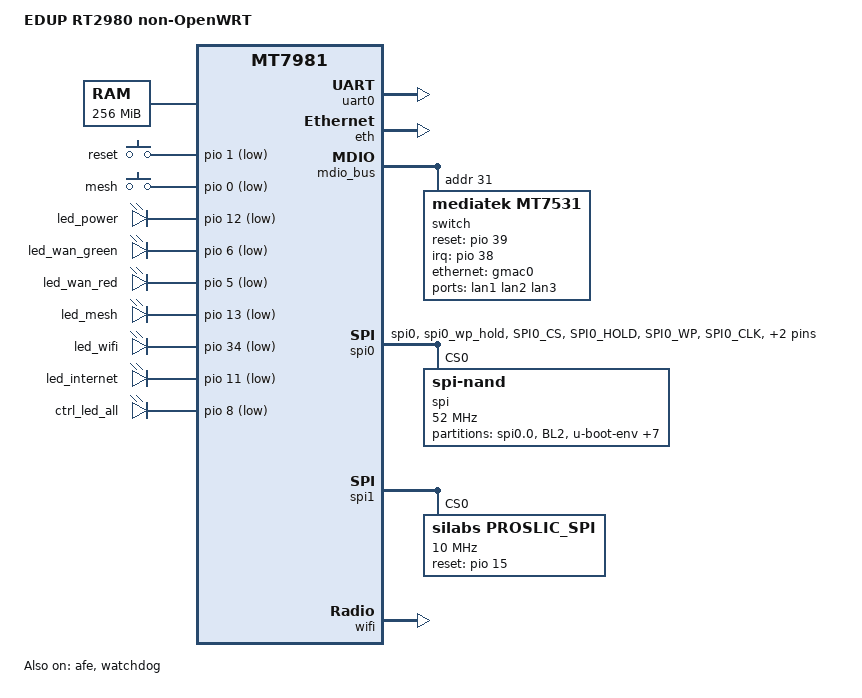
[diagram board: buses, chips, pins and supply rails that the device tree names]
// SPDX-License-Identifier: GPL-2.0-only OR MIT

/dts-v1/;
#include <dt-bindings/gpio/gpio.h>
#include <dt-bindings/input/input.h>
#include <dt-bindings/leds/common.h>

#include "mt7981.dtsi"

/ {
	model = "EDUP RT2980 non-OpenWRT";
	compatible = "edup,rt2980-non_openwrt", "mediatek,mt7981";

	aliases {
		led-boot = &power_led;
		led-failsafe = &power_led;
		led-running = &system_led;
		led-upgrade = &system_led;
		#label-mac-device = &gmac0;
		serial0 = &uart0;
	};

	chosen {
		bootargs = "console=ttyS0,115200n1 loglevel=8  \
				earlycon=uart8250,mmio32,0x11002000";
	};

	memory {
		reg = <0 0x40000000 0 0x10000000>;
	};

	gpio-keys {
		compatible = "gpio-keys";

		reset-button {
			label = "reset";
			linux,code = <KEY_RESTART>;
			gpios = <&pio 1 GPIO_ACTIVE_LOW>;
		};

		mesh-button {
			label = "mesh";
			linux,code = <BTN_9>;
			linux,input-type = <EV_SW>;
			gpios = <&pio 0 GPIO_ACTIVE_LOW>;
			debounce-interval = <60>;
		};
	};

	leds {
		compatible = "gpio-leds";

		power_led: power_red {
			label = "led_power";
			gpios = <&pio 12 GPIO_ACTIVE_LOW>;
			default-state = "on";
			linux,default-trigger = "default-on";
		};

		system_led: wan_green {
			label = "led_wan_green";
			gpios = <&pio 6 GPIO_ACTIVE_LOW>;
		};

		wan_red {
			label = "led_wan_red";
			gpios = <&pio 5 GPIO_ACTIVE_LOW>;
			linux,default-trigger = "phy1tpt";
		};

		mesh_blue {
			label = "led_mesh";
			gpios = <&pio 13 GPIO_ACTIVE_LOW>;
		};

		wifi_green {
			label = "led_wifi";
			gpios = <&pio 34 GPIO_ACTIVE_LOW>;
		};

		internet_blue {
			label = "led_internet";
			gpios = <&pio 11 GPIO_ACTIVE_LOW>;
		};

		all_ctrl {
			label = "ctrl_led_all";
			gpios = <&pio 8 GPIO_ACTIVE_LOW>;
			default-state = "on";
			linux,default-trigger = "default-on";
		};
	};
/*
	sound_wm8960 {
		compatible = "mediatek,mt79xx-wm8960-machine";
		mediatek,platform = <&afe>;
		audio-routing = "Headphone", "HP_L",
				"Headphone", "HP_R",
				"LINPUT1", "AMIC",
				"RINPUT1", "AMIC";
		mediatek,audio-codec = <&wm8960>;
		status = "disabled";
	};

	sound_si3218x {
		compatible = "mediatek,mt79xx-si3218x-machine";
		mediatek,platform = <&afe>;
		mediatek,ext-codec = <&proslic_spi>;
		status = "disabled";
	};
*/
/*
	gsw: gsw@0 {
		compatible = "mediatek,mt753x";
		mediatek,ethsys = <&ethsys>;
		#address-cells = <1>;
		#size-cells = <0>;
	};
*/
};

&afe {
	pinctrl-names = "default";
	pinctrl-0 = <&pcm_pins>;
	status = "okay";
};

&i2c0 {
	pinctrl-names = "default";
	pinctrl-0 = <&i2c_pins>;
	status = "disabled";

	wm8960: wm8960@1a {
		compatible = "wlf,wm8960";
		reg = <0x1a>;
	};
};

&uart0 {
	status = "okay";
};

&watchdog {
	status = "okay";
};

&eth {
	status = "okay";

	gmac0: mac@0 {
		compatible = "mediatek,eth-mac";
		reg = <0>;
		phy-mode = "2500base-x";

		fixed-link {
			speed = <2500>;
			full-duplex;
			pause;
		};
	};

	gmac1: mac@1 {
		compatible = "mediatek,eth-mac";
		reg = <1>;
		phy-mode = "gmii";
		phy-handle = <&int_gbe_phy>;
	};
};

&mdio_bus {
	switch: switch@1f {
		compatible = "mediatek,mt7531";
		reg = <31>;
		reset-gpios = <&pio 39 GPIO_ACTIVE_HIGH>;
		interrupt-controller;
		#interrupt-cells = <1>;
		interrupt-parent = <&pio>;
		interrupts = <38 IRQ_TYPE_LEVEL_HIGH>;
	};
};

&spi0 {
	pinctrl-names = "default";
	pinctrl-0 = <&spi0_flash_pins>;
	status = "okay";

	/* ESMT F50L1G41LB (128M) */
	spi: spi_nand@0 {
		#address-cells = <1>;
		#size-cells = <1>;
		compatible = "spi-nand";
		reg = <0>;

		spi-max-frequency = <52000000>;
		spi-tx-bus-width = <4>;
		spi-rx-bus-width = <4>;

		spi-cal-enable;
		spi-cal-mode = "read-data";
		spi-cal-datalen = <7>;
		spi-cal-data = /bits/ 8 <0x53 0x50 0x49 0x4e 0x41 0x4e 0x44>;
		spi-cal-addrlen = <5>;
		spi-cal-addr = /bits/ 32 <0x0 0x0 0x0 0x0 0x0>;

		partitions: partitions {
			compatible = "fixed-partitions";
			#address-cells = <1>;
			#size-cells = <1>;

			partition@0_all {
				label = "spi0.0";
				reg = <0x0 0x8000000>;
				read-only;
			};

			partition@0 {
				label = "BL2";
				reg = <0x00 0x100000>;
			};

			partition@100000 {
				label = "u-boot-env";
				reg = <0x100000 0x80000>;
			};

			partition@180000 {
				label = "Factory";
				reg = <0x180000 0x200000>;
			};

			partition@380000 {
				label = "FIP";
				reg = <0x380000 0x200000>;
			};

			partition@580000 {
				label = "ubi";
				reg = <0x580000 0x4000000>;
			};

			partition@4580000 {
				label = "pdt_data";
				reg = <0x4580000 0x0600000>;
				read-only;
			};

			partition@4b80000 {
				label = "pdt_data_1";
				reg = <0x4b80000 0x0600000>;
				read-only;
			};

			partition@5180000 {
				label = "exp";
				reg = <0x5180000 0x0100000>;
			};

			partition@5280000 {
				label = "plugin";
				reg = <0x5280000 0x2580000>;
			};
		};
	};
};

&spi1 {
	pinctrl-names = "default";
	pinctrl-0 = <&spic_pins>;
	status = "okay";

	proslic_spi: proslic_spi@0 {
		compatible = "silabs,proslic_spi";
		reg = <0>;
		spi-max-frequency = <10000000>;
		spi-cpha = <1>;
		spi-cpol = <1>;
		channel_count = <1>;
		debug_level = <4>;       /* 1 = TRC, 2 = DBG, 4 = ERR */
		reset_gpio = <&pio 15 0>;
		ig,enable-spi = <1>;     /* 1: Enable, 0: Disable */
	};
};

&switch {
	ports {
		#address-cells = <1>;
		#size-cells = <0>;

		port@0 {
			reg = <0>;
			label = "lan1";
		};

		port@1 {
			reg = <1>;
			label = "lan2";
		};

		port@2 {
			reg = <2>;
			label = "lan3";
		};

		port@6 {
			reg = <6>;
			ethernet = <&gmac0>;
			phy-mode = "2500base-x";

			fixed-link {
				speed = <2500>;
				full-duplex;
				pause;
			};
		};
	};
};

&pio {
	i2c_pins: i2c-pins-g0 {
		mux {
			function = "i2c";
			groups = "i2c0_0";
		};
	};

	pcm_pins: pcm-pins-g0 {
		mux {
			function = "pcm";
			groups = "pcm";
		};
	};

	pwm0_pin: pwm0-pin-g0 {
		mux {
			function = "pwm";
			groups = "pwm0_0";
		};
	};

	pwm1_pin: pwm1-pin-g0 {
		mux {
			function = "pwm";
			groups = "pwm1_0";
		};
	};

	pwm2_pin: pwm2-pin {
		mux {
			function = "pwm";
			groups = "pwm2";
		};
	};

	spi0_flash_pins: spi0-pins {
		mux {
			function = "spi";
			groups = "spi0", "spi0_wp_hold";
		};

		conf-pu {
			pins = "SPI0_CS", "SPI0_HOLD", "SPI0_WP";
			drive-strength = <MTK_DRIVE_8mA>;
			bias-pull-up = <MTK_PUPD_SET_R1R0_11>;
		};

		conf-pd {
			pins = "SPI0_CLK", "SPI0_MOSI", "SPI0_MISO";
			drive-strength = <MTK_DRIVE_8mA>;
			bias-pull-down = <MTK_PUPD_SET_R1R0_11>;
		};
	};

	uart1_pins: uart1-pins-g1 {
		mux {
			function = "uart";
			groups = "uart1_1";
		};
	};

	uart2_pins: uart2-pins-g1 {
		mux {
			function = "uart";
			groups = "uart2_1";
		};
	};
};
/*
&pcie {
	pinctrl-names = "default";
	pinctrl-0 = <&pcie_pins>;
	status = "okay";
};
*/
&wifi {
	status = "okay";
};
